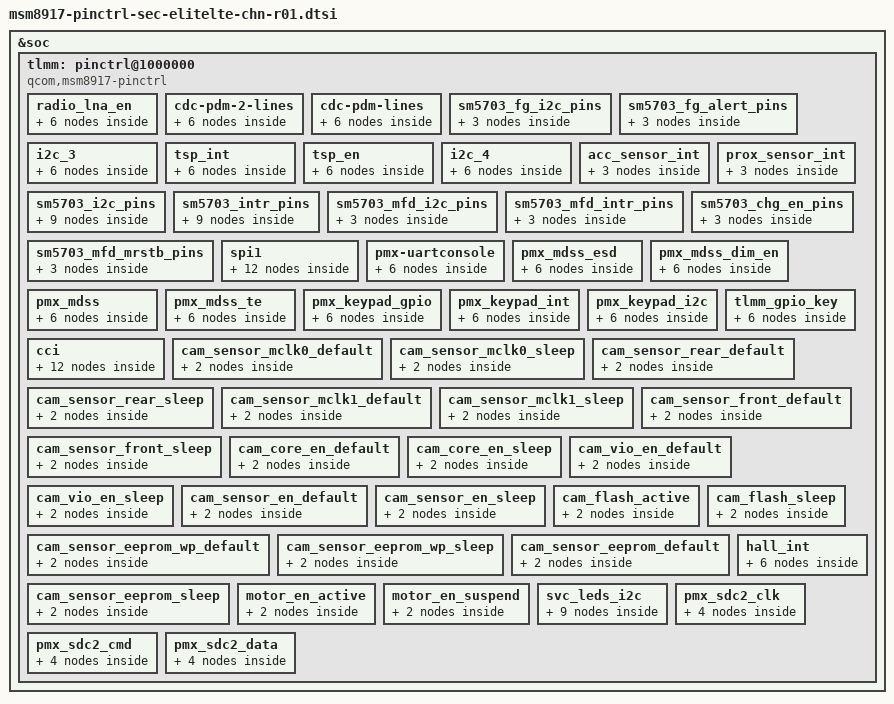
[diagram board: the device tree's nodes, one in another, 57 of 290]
/*
 * Copyright (c) 2015, The Linux Foundation. All rights reserved.
 *
 * This program is free software; you can redistribute it and/or modify
 * it under the terms of the GNU General Public License version 2 and
 * only version 2 as published by the Free Software Foundation.
 *
 * This program is distributed in the hope that it will be useful,
 * but WITHOUT ANY WARRANTY; without even the implied warranty of
 * MERCHANTABILITY or FITNESS FOR A PARTICULAR PURPOSE.  See the
 * GNU General Public License for more details.
 */

/*#include "../../qcom/msm8917-pinctrl.dtsi" */

&soc {
	tlmm: pinctrl@1000000 {
		compatible = "qcom,msm8917-pinctrl";
		reg = <0x1000000 0x300000>;
		interrupts = <0 208 0>;
		gpio-controller;
		#gpio-cells = <2>;
		interrupt-controller;
		#interrupt-cells = <2>;

		radio_lna_en {
				lna_en_default: lna_en_default {
					mux {
						pins = "gpio104";
						function = "gpio";
					};

					config {
						pins = "gpio104";
						drive-strength = <2>;
						bias-disable;
					};
				};
				lna_en_sleep: lna_en_sleep {
					mux {
						pins = "gpio104";
						function = "gpio";
					};

					config {
						pins = "gpio104";
						drive-strength = <2>;
						bias-disable;
					};
				};
		};

		cdc-pdm-2-lines {
			cdc_pdm_lines_2_act: pdm_lines_2_on {
				mux {
					pins = "gpio70", "gpio71", "gpio72";
					function = "cdc_pdm0";
				};

				config {
					pins = "gpio70", "gpio71", "gpio72";
					drive-strength = <8>;
					bias-pull-down;
				};
			};

			cdc_pdm_lines_2_sus: pdm_lines_2_off {
				mux {
					pins = "gpio70", "gpio71", "gpio72";
					function = "cdc_pdm0";
				};

				config {
					pins = "gpio70", "gpio71", "gpio72";
					drive-strength = <2>;
					bias-pull-down;
				};
			};
		};

		cdc-pdm-lines {
			cdc_pdm_lines_act: pdm_lines_on {
				mux {
					pins = "gpio69", "gpio73", "gpio74";
					function = "cdc_pdm0";
				};

				config {
					pins = "gpio69", "gpio73", "gpio74";
					drive-strength = <8>;
					bias-pull-down;
				};
			};
			cdc_pdm_lines_sus: pdm_lines_off {
				mux {
					pins = "gpio69", "gpio73", "gpio74";
					function = "cdc_pdm0";
				};

				config {
					pins = "gpio69", "gpio73", "gpio74";
					drive-strength = <2>;
					bias-pull-down;
				};
			};
		};

		/* Fuelgauge I2C pins */
		sm5703_fg_i2c_pins {

			sm5703_fg_i2c_default: default {
				/* default state */
				mux {
					pins = "gpio6", "gpio7";
					function = "gpio";
				};

				config {
					pins = "gpio6", "gpio7";
					drive-strength = <2>;
					bias-disable;
				};
			};

		};

		/* Fuelgauge alert pin */
                sm5703_fg_alert_pins {

                        sm5703_fg_alert_default: default {
                                /* default state */
                                mux {
                                        pins = "gpio63";
                                        function = "gpio";
                                };

                                config {
                                        pins = "gpio63";
                                        drive-strength = <2>;
                                        bias-disable;
                                };
                        };

                };

		/* pingrp for tsp - start */
		i2c_3 {
			i2c_3_active: i2c_3_active {
				/* active state */
				mux {
					pins = "gpio10", "gpio11";
					function = "blsp_i2c3";
				};

				config {
					pins = "gpio10", "gpio11";
					drive-strength = <2>;
					bias-disable;
				};
			};

			i2c_3_sleep: i2c_3_sleep {
				/* suspended state */
				mux {
					pins = "gpio10", "gpio11";
					function = "blsp_i2c3";
				};

				config {
					pins = "gpio10", "gpio11";
					drive-strength = <2>;
					bias-pull-down;
				};
			};
		};

		tsp_int {
			tsp_int_active: tsp_int_active {
				mux {
					pins = "gpio65";
					function = "gpio";
				};

				config {
					pins = "gpio65";
					drive-strength = <2>;
					bias-disable;
				};
			};
			tsp_int_suspend: tsp_int_suspend {
				mux {
					pins = "gpio65";
					function = "gpio";
				};

				config {
					pins = "gpio65";
					drive-strength = <2>;
					bias-pull-down;
				};
			};
		};

		tsp_en {
			tsp_avdd_gpio: tsp_avdd_gpio {
				mux {
					pins = "gpio64";
					function = "gpio";
				};

				config {
					pins = "gpio64";
					drive-strength = <2>;
					bias-disable;
					output-low;
				};
			};
			tsp_vddo_gpio: tsp_vddo_gpio {
				mux {
					pins = "gpio95";
					function = "gpio";
				};

				config {
					pins = "gpio95";
					drive-strength = <2>;
					bias-disable;
					output-low;
				};
			};
		};

		/* pingrp for sensor - start */
		i2c_4 {
			i2c_4_active: i2c_4_active {
				/* active state */
				mux {
					pins = "gpio14", "gpio15";
					function = "blsp_i2c4";
				};

				config {
					pins = "gpio14", "gpio15";
					drive-strength = <2>;
					bias-disable;
				};
			};

			i2c_4_sleep: i2c_4_sleep {
				/* suspended state */
				mux {
					pins = "gpio14", "gpio15";
					function = "blsp_i2c4";
				};

				config {
					pins = "gpio14", "gpio15";
					drive-strength = <2>;
					bias-disable;
				};
			};
		};

		acc_sensor_int {
			acc_int_active: default {
				mux {
					pins = "gpio42";
					function = "gpio";
				};

				config {
					pins = "gpio42";
					drive-strength = <2>;
					bias-pull-down;
				};
			};
		};
		prox_sensor_int {
			prox_int_active: default {
				mux {
					pins = "gpio43";
					function = "gpio";
				};

				config {
					pins = "gpio43";
					drive-strength = <2>;
					bias-disable;
				};
			};
		};
		/* pingrp for sensor - end */

			/* MUIC - SM5703 */
		sm5703_i2c_pins {
			sm5703_i2c_default: default {
				/* default state*/
				mux {
					pins = "gpio16", "gpio17"; /* SDA, SCL */
                        		function = "gpio";
				};
				config {
					pins = "gpio16", "gpio17";
					drive-strength = <2>;
					bias-disable;
				};
			};

			sm5703_i2c_active: active {
				/*active state*/
				 mux {
                                        pins = "gpio16", "gpio17"; /* SDA, SCL */
                                        function = "gpio";
                                };
                                config {
                                        pins = "gpio16", "gpio17";
                                        drive-strength = <2>;
                                        bias-disable;
                                };

			};
			sm5703_i2c_suspend: suspend {
				/*suspend state*/
				 mux {
                                        pins = "gpio16", "gpio17"; /* SDA, SCL */
                                        function = "gpio";
                                };
                                config {
                                        pins = "gpio16", "gpio17";
                                        drive-strength = <2>;
                                        bias-disable;
                                };

			};
		};

		sm5703_intr_pins {
			sm5703_interrupt_default: sm5703_interrupt_default {
				/*default state*/
				mux {
					pins = "gpio28";
					function = "gpio";
				};
				config {
					pins = "gpio28";
					drive-strength = <2>;
					bias-disable;
				};
			};

			sm5703_interrupt_active: sm5703_interrupt_active {
				/*active state*/
				mux {
                                        pins = "gpio28";
                                        function = "gpio";
                                };
                                config {
                                        pins = "gpio28";
                                        drive-strength = <2>;
                                        bias-disable;
                                };

			};
			sm5703_interrupt_suspend: sm5703_interrupt_suspend {
				/*suspend state*/
				 mux {
                                        pins = "gpio28";
                                        function = "gpio";
                                };
                                config {
                                        pins = "gpio28";
                                        drive-strength = <2>;
                                        bias-disable;
                                };
			};
		};

		sm5703_mfd_i2c_pins {
			sm5703_mfd_i2c_default: default {
				/* default state*/
				mux {
					pins = "gpio18", "gpio19"; /* SDA, SCL */
                        		function = "gpio";
				};
				config {
					pins = "gpio18", "gpio19";
					drive-strength = <2>;
					bias-disable;
				};
			};
		};
		sm5703_mfd_intr_pins {
			sm5703_mfd_interrupt_default: sm5703_mfd_interrupt_default {
				/*default state*/
				mux {
					pins = "gpio35";
					function = "gpio";
				};
				config {
					pins = "gpio35";
					drive-strength = <2>;
					bias-disable;
				};
			};
		};

		sm5703_mfd_mrstb_pins {
			sm5703_mfd_mrstb_default: sm5703_mfd_mrstb_default {
				/*default state*/
				mux {
					pins = "gpio125";
					function = "gpio";
				};
				config {
					pins = "gpio125";
					drive-strength = <2>;
					bias-disable;
				};
			};
		};

		/* Chg_en pin */
                sm5703_chg_en_pins {
                        sm5703_chg_en_default: sm5703_chg_en_default {
                                /* default state */
                                mux {
                                        pins = "gpio129";
                                        function = "gpio";
                                };
                                config {
                                        pins = "gpio129";
                                        drive-strength = <2>;
                                        bias-disable;
					output-low;
                                };
                        };
                };

		spi1 {
			spi1_default: spi1_default {
				/* active state */
				mux {
					/* MOSI, MISO, CLK */
					pins = "gpio0", "gpio1", "gpio3";
					function = "blsp_spi1";
				};

				config {
					pins = "gpio0", "gpio1", "gpio3";
					drive-strength = <2>; /* 12 MA */
					bias-disable = <0>; /* No PULL */
					input-low;
				};
			};

			spi1_sleep: spi1_sleep {
				/* suspended state */
				mux {
					/* MOSI, MISO, CLK */
					pins = "gpio0", "gpio1", "gpio3";
					function = "gpio";
				};

				config {
					pins = "gpio0", "gpio1", "gpio3";
					drive-strength = <2>; /* 2 MA */
					bias-pull-down; /* PULL Down */
					input-low;
				};
			};

			spi1_cs0_active: cs0_active {
				/* CS */
				mux {
					pins = "gpio2";
					function = "blsp_spi1";
				};

				config {
					pins = "gpio2";
					drive-strength = <2>;
					bias-disable = <0>;
				};
			};

			spi1_cs0_sleep: cs0_sleep {
				/* CS */
				mux {
					pins = "gpio2";
					function = "gpio";
				};

				config {
					pins = "gpio2";
					drive-strength = <2>;
					bias-disable = <0>;
				};
			};
		};
		
		pmx-uartconsole {
			uart_console_active: uart_console_active {
				mux {
					pins = "gpio4", "gpio5";
					function = "blsp_uart2";
				};

				config {
					pins = "gpio4", "gpio5";
					drive-strength = <2>;
					bias-disable;
				};
			};

			uart_console_sleep: uart_console_sleep {
				mux {
					pins = "gpio4", "gpio5";
					function = "blsp_uart2";
				};

				config {
					pins = "gpio4", "gpio5";
					drive-strength = <2>;
					bias-pull-down;
				};
			};
		};

		pmx_mdss_esd: pmx_mdss_esd {
			mdss_esd_active: mdss_esd_active {
				mux {
					pins = "gpio90";
					function = "gpio";
				};

				config {
					pins = "gpio90";
					drive-strength = <8>; /* 8 mA */
					bias-disable; /* NO pull */
					input-low;
				};
			};
			mdss_esd_suspend: mdss_esd_suspend {
				mux {
					pins = "gpio90";
				};

				config {
					pins = "gpio90";

					drive-strength = <2>; /* 2 mA */
					bias-disable; /* NO pull */
					input-high;
				};
			};
		};
		pmx_mdss_dim_en: pmx_mdss_dim_en {
			mdss_dim_active: mdss_dim_active {
				mux {
					pins = "gpio45";
					function = "gpio";
				};

				config {
					pins = "gpio45";
					drive-strength = <8>; /* 8 mA */
					bias-pull-down; /* pull down*/
					input-low;
				};
			};
			mdss_dim_suspend: mdss_dim_suspend {
				mux {
					pins = "gpio45";
				};

				config {
					pins = "gpio45";

					drive-strength = <2>; /* 2 mA */
					bias-disable; /* NO pull */
					output-low;
				};
			};
		};
		pmx_mdss: pmx_mdss {
			/* ON_CELL panel control LCD  power */
			mdss_dsi_active: mdss_dsi_active {
				mux {
					pins =
					/* LCD,BLIC */
					"gpio60", "gpio62", "gpio95";
					function = "gpio";
				};

				config {
					pins =
					/* LCD,BLIC */
					"gpio60", "gpio62", "gpio95";

					drive-strength = <8>; /* 8 mA */
					bias-disable; /* NO pull */
					output-high;
				};
			};
			mdss_dsi_suspend: mdss_dsi_suspend {
				mux {
					pins =
					/* LCD,BLIC */
					"gpio60", "gpio62", "gpio95";
					function = "gpio";
				};

				config {
					pins =
					/* LCD,BLIC */
					"gpio60", "gpio62", "gpio95";

					drive-strength = <2>; /* 2 mA */
					bias-disable; /* NO pull */
					output-low;
				};
			};
		};

		pmx_mdss_te: pmx_mdss_te {
			mdss_te_active: mdss_te_active {
				mux {
					pins = "gpio24";
					function = "mdp_vsync";
				};
				config {
					pins = "gpio24";
					drive-strength = <2>; /* 8 mA */
					bias-pull-down; /* pull down*/
				};
			};

			mdss_te_suspend: mdss_te_suspend {
				mux {
					pins = "gpio24";
					function = "mdp_vsync";
				};
				config {
					pins = "gpio24";
					drive-strength = <2>; /* 2 mA */
					bias-pull-down; /* pull down */
				};
			};
		};

		/* add pingrp for keypad */
		pmx_keypad_gpio {
			keypad_en_gpio: keypad_en_gpio {
				mux {
					pins = "gpio24";
					function = "gpio";
				};

				config {
					pins = "gpio24";
					drive-strength = <2>;
					bias-disable;
					output-low;
				};
			};
			keypad_led_gpio: keypad_led_gpio {
				mux {
					pins = "gpio92";
					function = "gpio";
				};

				config {
					pins = "gpio92";
					drive-strength = <2>;
					bias-disable;
					output-low;
				};
			};
		};

		pmx_keypad_int {
			keypad_int_active: keypad_int_active {
				mux {
					pins = "gpio48";
					function = "gpio";
				};

				config {
					pins = "gpio48";
					drive-strength = <8>;
					bias-disable; /* NO pull */
				};
			};
			keypad_int_suspend: keypad_int_suspend {
				mux {
					pins = "gpio48";
					function = "gpio";
				};

				config {
					pins = "gpio48";
					drive-strength = <2>;
					bias-disable; /* NO pull */
				};
			};
		};

		pmx_keypad_i2c {
			keypad_i2c_active: keypad_i2c_active {
				mux {
					pins = "gpio87",  "gpio88";
					function = "gpio";
				};

				config {
					pins = "gpio87",  "gpio88";
					drive-strength = <8>;
					bias-disable; /* NO pull */
				};
			};
			keypad_i2c_suspend: keypad_i2c_suspend {
				mux {
					pins = "gpio87",  "gpio88";
					function = "gpio";
				};

				config {
					pins = "gpio87",  "gpio88";
					drive-strength = <2>;
					bias-disable; /* NO pull */
				};
			};
		};

		tlmm_gpio_key {
			gpio_key_active: gpio_key_active {
				mux {
					pins = "gpio127";
					function = "gpio";
				};

				config {
					pins = "gpio127";
					drive-strength = <2>;
					bias-pull-up; /* pull up */
				};
			};

			gpio_key_suspend: gpio_key_suspend {
				mux {
					pins = "gpio127";
					function = "gpio";
				};

				config {
					pins = "gpio127";
					drive-strength = <2>;
					bias-pull-up; /* pull up */
				};
			};
		};

		cci {
			cci0_active: cci0_active {
				/* cci0 active state */
				mux {
					/* CLK, DATA */
					pins = "gpio29", "gpio30";
					function = "cci_i2c";
				};

				config {
					pins = "gpio29", "gpio30";
					drive-strength = <2>; /* 2 MA */
					bias-disable; /* No PULL */
				};
			};

			cci0_suspend: cci0_suspend {
				/* cci0 suspended state */
				mux {
					/* CLK, DATA */
					pins = "gpio29", "gpio30";
					function = "gpio";
				};

				config {
					pins = "gpio29", "gpio30";
					drive-strength = <2>; /* 2 MA */
					bias-disable; /* No PULL */
				};
			};

			cci1_active: cci1_active {
				/* cci1 active state */
				mux {
					/* CLK, DATA */
					pins = "gpio31", "gpio32";
					function = "cci_i2c";
				};

				config {
					pins = "gpio31", "gpio32";
					drive-strength = <2>; /* 2 MA */
					bias-disable; /* No PULL */
				};
			};

			cci1_suspend: cci1_suspend {
				/* cci1 suspended state */
				mux {
					/* CLK, DATA */
					pins = "gpio31", "gpio32";
					function = "gpio";
				};

				config {
					pins = "gpio31", "gpio32";
					drive-strength = <2>; /* 2 MA */
					bias-disable; /* No PULL */
				};
			};
		};

		/*sensors */
		cam_sensor_mclk0_default: cam_sensor_mclk0_default {
			/* MCLK0 */
			mux {
				/* CLK, DATA */
				pins = "gpio26";
				function = "cam_mclk";
			};

			config {
				pins = "gpio26";
				bias-disable; /* No PULL */
				drive-strength = <2>; /* 2 MA */
			};
		};

		cam_sensor_mclk0_sleep: cam_sensor_mclk0_sleep {
			/* MCLK0 */
			mux {
				/* CLK, DATA */
				pins = "gpio26";
				function = "gpio";
			};

			config {
				pins = "gpio26";
				bias-disable; /* NO PULL */
				drive-strength = <2>; /* 2 MA */
				output-low;
			};
		};

		cam_sensor_rear_default: cam_sensor_rear_default {
			/* RESET, STANDBY */
			mux {
				pins = "gpio36";
				function = "gpio";
			};

			config {
				pins = "gpio36";
				bias-disable; /* NO PULL */
				drive-strength = <2>; /* 2 MA */
				output-low;
			};
		};

		cam_sensor_rear_sleep: cam_sensor_rear_sleep {
			/* RESET, STANDBY */
			mux {
				pins = "gpio36";
				function = "gpio";
			};

			config {
				pins = "gpio36";
				bias-disable; /* NO PULL */
				drive-strength = <2>; /* 2 MA */
				output-low;
			};
		};

		cam_sensor_mclk1_default: cam_sensor_mclk1_default {
			/* MCLK1 */
			mux {
				/* CLK, DATA */
				pins = "gpio27";
				function = "cam_mclk";
			};

			config {
				pins = "gpio27";
				bias-disable; /* No PULL */
				drive-strength = <4>; /* MA */
			};
		};

		cam_sensor_mclk1_sleep: cam_sensor_mclk1_sleep {
			/* MCLK1 */
			mux {
				/* CLK, DATA */
				pins = "gpio27";
				function = "gpio";
			};

			config {
				pins = "gpio27";
				bias-disable; /* NO PULL */
				drive-strength = <4>; /* MA */
				output-low;
			};
		};

		cam_sensor_front_default: cam_sensor_front_default {
			/* RESET, STANDBY */
			mux {
				pins = "gpio38";
				function = "gpio";
			};

			config {
				pins = "gpio38";
				bias-disable; /* NO PULL */
				drive-strength = <2>; /* 2 MA */
				output-low;
			};
		};

		cam_sensor_front_sleep: cam_sensor_front_sleep {
			/* RESET, STANDBY */
			mux {
				pins = "gpio38";
				function = "gpio";
			};

			config {
				pins = "gpio38";
				bias-disable; /* NO PULL */
				drive-strength = <2>; /* 2 MA */
				output-low;
			};
		};

		cam_core_en_default: cam_core_en_default {
			mux {
				pins = "gpio86";
				function = "gpio";
			};

			config {
				pins = "gpio86";
				bias-disable; /* NO PULL */
				drive-strength = <2>;
				output-low;
			};
		};

		cam_core_en_sleep: cam_core_en_sleep {
			mux {
				pins = "gpio86";
				function = "gpio";
			};

			config {
				pins = "gpio86";
				bias-disable; /* NO PULL */
				drive-strength = <2>;
				output-low;
			};
		};

		cam_vio_en_default: cam_vio_en_default {
			/* VIO */
			mux {
				pins = "gpio39";
				function = "gpio";
			};

			config {
				pins = "gpio39";
				bias-pull-down; /* PULL DOWN */
				drive-strength = <2>; /* 2 MA */
				output-low;
			};
		};

		cam_vio_en_sleep: cam_vio_en_sleep {
			/* VDIO */
			mux {
				pins = "gpio39";
				function = "gpio";
			};

			config {
				pins = "gpio39";
				bias-pull-down; /* PULL DOWN */
				drive-strength = <2>; /* 2 MA */
				output-low;
			};
		};

		cam_sensor_en_default: cam_sensor_en_default {
			/* VIO */
			mux {
				pins = "gpio9";
				function = "gpio";
			};

			config {
				pins = "gpio9";
				bias-disable; /* NO PULL */
				drive-strength = <2>; /* 2 MA */
				output-low;
			};
		};

		cam_sensor_en_sleep: cam_sensor_en_sleep {
			/* VDIO */
			mux {
				pins = "gpio9";
				function = "gpio";
			};

			config {
				pins = "gpio9";
				bias-disable; /* No PULL */
				drive-strength = <2>; /* 2 MA */
				output-low;
			};
		};

		cam_flash_active: cam_flash_active {
			/* TORCH, FLASH */
			mux {
				pins = "gpio34", "gpio33";
				function = "gpio";
			};

			config {
				pins = "gpio34", "gpio33";
				bias-pull-down; /* PULL DOWN */
				drive-strength = <2>; /* 2 MA */
				output-low;
			};
		};

		cam_flash_sleep: cam_flash_sleep {
			/* TORCH, FLASH */
			mux {
				pins = "gpio34", "gpio33";
				function = "gpio";
			};

			config {
				pins = "gpio34", "gpio33";
				bias-pull-down; /* PULL DOWN */
				drive-strength = <2>; /* 2 MA */
				output-low;
			};
		};


		cam_sensor_eeprom_wp_default: cam_sensor_eeprom_wp_default {
			mux {
				pins = "gpio85";
				function = "gpio";
			};

			config {
				pins = "gpio85";
				bias-disable;
				drive-strength = <4>;
				output-low;
			};
		};

		cam_sensor_eeprom_wp_sleep: cam_sensor_eeprom_wp_sleep {
			mux {
				pins = "gpio85";
				function = "gpio";
			};

			config {
				pins = "gpio85";
				bias-pull-down;
				drive-strength = <4>;
				output-low;
			};
		};

		cam_sensor_eeprom_default: cam_sensor_eeprom_default {
			mux {
				pins = "gpio22", "gpio23";
				function = "gpio";
			};

			config {
				pins = "gpio22", "gpio23";
				bias-disable;
				drive-strength = <4>;
				output-low;
			};
		};

		cam_sensor_eeprom_sleep: cam_sensor_eeprom_sleep {
			mux {
				pins = "gpio22", "gpio23";
				function = "gpio";
			};

			config {
				pins = "gpio22", "gpio23";
				bias-pull-down;
				drive-strength = <4>;
				output-low;
			};
		};

		/* add pinctrl for motor  */
		motor_en_active: motor_en_active {
			mux {
				pins = "gpio40";
				function = "gpio";
			};

			config {
				pins = "gpio40";
				bias-pull-down;
				drive-strength = <2>;
				output-high;
			};
		};

		motor_en_suspend: motor_en_suspend {
			mux {
				pins = "gpio40";
				function = "gpio";
			};

			config {
				pins = "gpio40";
				bias-pull-down;
				drive-strength = <2>;
				output-low;
			};
		};

		hall_int {
			hall_int_default: default {
				mux {
					pins = "gpio97";
					function = "gpio";
				};

				config {
					pins = "gpio97";
					bias-disable;
					drive-strength = <2>;
				};
        		};

			hall_int_sleep: sleep {
				mux {
					pins = "gpio97";
					function = "gpio";
				};

				config {
					pins = "gpio97";
					bias-disable;
					drive-strength = <2>;
				};
        		};
		};

		svc_leds_i2c {
			svc_leds_i2c_active: active {
				mux {
					pins = "gpio12" , "gpio13"; /* SDA, SCL */
					function = "NA";
				};

				config {
					pins = "gpio12", "gpio13";
					bias-disable;
					drive-strength = <2>;
				};
			};

			svc_leds_i2c_suspend: suspend {
				mux {
					pins = "gpio12" , "gpio13"; /* SDA, SCL */
					function = "NA";
				};

				config {
					pins = "gpio12", "gpio13";
					bias-disable;
					drive-strength = <2>;
				};
			};

			svc_leds_int: init {
				mux {
					pins = "gpio8";
					function = "gpio";
				};

				config {
					pins = "gpio8";
					bias-disable;
					drive-strength = <2>;
					output-high;
				};
        		};
		};

                pmx_sdc2_clk {
                        sdc2_clk_on: sdc2_clk_on {
                                config {
                                        pins = "sdc2_clk";
                                        drive-strength = <10>; /* 10 MA */
                                        bias-disable; /* NO pull */
                                };
                        };

                        sdc2_clk_off: sdc2_clk_off {
                                config {
                                        pins = "sdc2_clk";
                                        bias-disable; /* NO pull */
                                        drive-strength = <2>; /* 2 MA */
                                };
                        };
                };

                pmx_sdc2_cmd {
                        sdc2_cmd_on: sdc2_cmd_on {
                                config {
                                        pins = "sdc2_cmd";
                                        bias-pull-up; /* pull up */
                                        drive-strength = <8>; /* 8 MA */
                                };
                        };

                        sdc2_cmd_off: sdc2_cmd_off {
                                config {
                                        pins = "sdc2_cmd";
                                        bias-pull-up; /* pull up */
                                        drive-strength = <2>; /* 2 MA */
                                };
                        };
                };

                pmx_sdc2_data {
                        sdc2_data_on: sdc2_data_on {
                                config {
                                        pins = "sdc2_data";
                                        bias-pull-up; /* pull up */
                                        drive-strength = <8>; /* 8 MA */
                                };
                        };

                        sdc2_data_off: sdc2_data_off {
                                config {
                                        pins = "sdc2_data";
                                        bias-pull-up; /* pull up */
                                        drive-strength = <2>; /* 2 MA */
                                };
                         };
                };
	};
};
